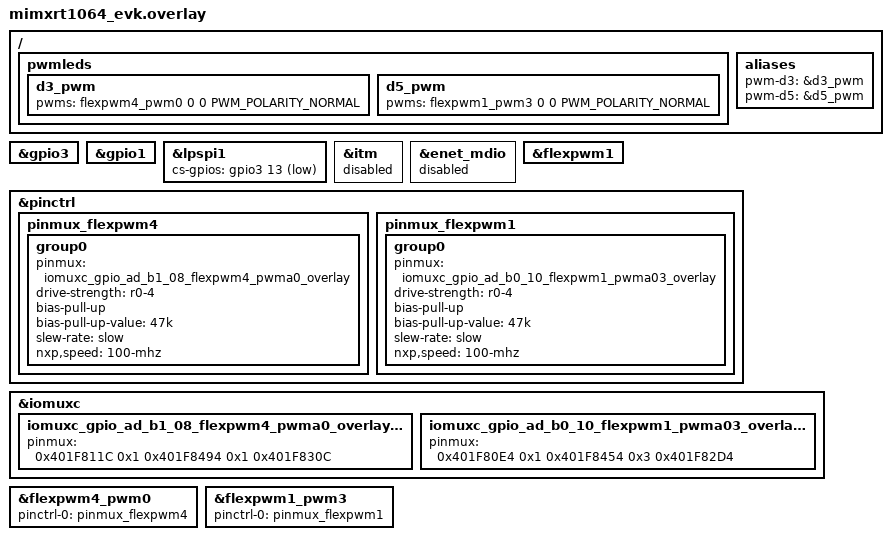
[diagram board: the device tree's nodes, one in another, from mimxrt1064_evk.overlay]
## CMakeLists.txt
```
# SPDX-License-Identifier: Apache-2.0

cmake_minimum_required(VERSION 3.20.0)

find_package(Zephyr REQUIRED HINTS $ENV{ZEPHYR_BASE})
project(serial)

if(NOT DEFINED SELECTED_PROJECT)
    message(FATAL_ERROR "Please specify a project to build with -DSELECTED_PROJECT=<PROJECT_NAME>")
endif()

if(SELECTED_PROJECT STREQUAL "I2C_OLED")
    target_sources(app PRIVATE Projects/I2C_OLED/src/main.cpp Projects/I2C_OLED/src/oled.cpp)
    target_include_directories(app PRIVATE Projects/I2C_OLED/include)

elseif(SELECTED_PROJECT STREQUAL "ST1140")
    target_sources(app PRIVATE Projects/ST1140/main.cpp)

elseif(SELECTED_PROJECT STREQUAL "HCSR04")
    target_sources(app PRIVATE Projects/HCSR04/main.cpp)

elseif(SELECTED_PROJECT STREQUAL "SPI_NRF24L01")
    target_sources(app PRIVATE Projects/SPI_NRF24L01/src/main.cpp Projects/SPI_NRF24L01/src/nrf24.cpp)
    target_include_directories(app PRIVATE Projects/SPI_NRF24L01/include)

elseif(SELECTED_PROJECT STREQUAL "UART_BRIDGE")
    target_sources(app PRIVATE Projects/UART_BRIDGE/src/main.cpp Projects/UART_BRIDGE/src/uart_bridge.cpp)
    target_include_directories(app PRIVATE Projects/UART_BRIDGE/include)

elseif(SELECTED_PROJECT STREQUAL "AHT40")
    target_sources(app PRIVATE Projects/AHT40/src/main.cpp Projects/AHT40/src/aht40.cpp)
    target_include_directories(app PRIVATE Projects/AHT40/include)

else()
    message(FATAL_ERROR "Unknown project: ${SELECTED_PROJECT}")
endif()
```

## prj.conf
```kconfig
CONFIG_PRINTK=y
CONFIG_CBPRINTF_FP_SUPPORT=y
CONFIG_CPP=y
CONFIG_GPIO=y
CONFIG_SPI=y
CONFIG_PWM=y
CONFIG_ADC=y
CONFIG_COUNTER=y
CONFIG_STD_CPP17=y
CONFIG_NEWLIB_LIBC=y
CONFIG_LOG=y
CONFIG_LOG_MODE_MINIMAL=y
```

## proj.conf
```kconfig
CONFIG_PRINTK=y
CONFIG_CBPRINTF_FP_SUPPORT=y
CONFIG_CPP=y
CONFIG_I2C=y
CONFIG_GPIO=y
CONFIG_SPI=y
```

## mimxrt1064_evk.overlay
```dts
&gpio3 {
    status = "okay";
};

&gpio1 {
    status = "okay";
};

&lpspi1 {
    status = "okay";
    cs-gpios = <&gpio3 13 GPIO_ACTIVE_LOW>;
};

&itm {
    status = "disabled";
};

&enet_mdio {
    status = "disabled";
};

&flexpwm1 {
    status = "okay";
};

&pinctrl {
    /* Konfiguracja pinmux dla GPIO_AD_B1_08 */
    pinmux_flexpwm4: pinmux_flexpwm4 {
        group0 {
            pinmux = <&iomuxc_gpio_ad_b1_08_flexpwm4_pwma0_overlay>;
            drive-strength = "r0-4";
            bias-pull-up;
            bias-pull-up-value = "47k";
            slew-rate = "slow";
            nxp,speed = "100-mhz";
        };
    };
    
    /* Konfiguracja pinmux dla GPIO_AD_B0_10 */
    pinmux_flexpwm1: pinmux_flexpwm1 {
        group0 {
            pinmux = <&iomuxc_gpio_ad_b0_10_flexpwm1_pwma03_overlay>;
            drive-strength = "r0-4";
            bias-pull-up;
            bias-pull-up-value = "47k";
            slew-rate = "slow";
            nxp,speed = "100-mhz";
        };
    };
};

/* Konfiguracja pinu GPIO_AD_B1_08 na IOMUXC_GPIO_AD_B1_08_FLEXPWM4_PWMA00 */
&iomuxc {
    iomuxc_gpio_ad_b1_08_flexpwm4_pwma0_overlay: IOMUXC_GPIO_AD_B1_08_FLEXPWM4_PWMA00 {
        pinmux = <0x401F811C 0x1 0x401F8494 0x1 0x401F830C>;
    };
};

/* Konfiguracja pinu GPIO_AD_B0_10 na IOMUXC_GPIO_AD_B0_10_FLEXPWM1_PWMA03 */
&iomuxc {
    iomuxc_gpio_ad_b0_10_flexpwm1_pwma03_overlay: IOMUXC_GPIO_AD_B0_10_FLEXPWM1_PWMA03 {
        pinmux = <0x401F80E4 0x1 0x401F8454 0x3 0x401F82D4>;
    };
};

/* Konfiguracja FLEXPWM dla GPIO_AD_B1_08 (D3)*/
&flexpwm4_pwm0 {
    status = "okay";
    pinctrl-0 = <&pinmux_flexpwm4>;
    pinctrl-names = "default";
};

/* Konfiguracja FLEXPWM dla GPIO_AD_B0_10 (D5) */
&flexpwm1_pwm3 {
    status = "okay";
    pinctrl-0 = <&pinmux_flexpwm1>;
    pinctrl-names = "default";
};

/ { 
    pwmleds {
        d3_pwm: d3_pwm {
            pwms = <&flexpwm4_pwm0 0 0 PWM_POLARITY_NORMAL>;
        };

        d5_pwm: d5_pwm {
            pwms = <&flexpwm1_pwm3 0 0 PWM_POLARITY_NORMAL>;
        };
    };
};

/ {
    aliases {
        pwm-d3 = &d3_pwm; /* PWM na D3 (GPIO_AD_B1_08) */
        pwm-d5 = &d5_pwm; /* PWM na D5 (GPIO_AD_B0_10) */
    };
};
```

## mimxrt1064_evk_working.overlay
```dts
&qtmr1_timer0 {
    status = "okay";
    mode = "kQTMR_PriSrcRiseEdge";
    primary_source = "kQTMR_ClockDivide_128";
};

&pit0_channel0 {
    status = "okay";
};

&csi {
    status = "disabled";
};

&pinmux_csi {
    group1 {
        pinmux = <>;
    };
};

&flexcan1 {
    status = "disabled";
};

&pinmux_flexcan1 {
    group0 {
        pinmux = <>;
    };
};

&pinctrl {
    pinmux_flexpwm4: pinmux_flexpwm4 {
        pinmux = <
            0x401F811C 0x1 0x401F8494 0x1 0x401F830C 0x10B0
        >;
    };
};

&flexpwm4_pwm0 {
    status = "okay";
    pinctrl-0 = <&pinmux_flexpwm4>;
    pinctrl-names = "default";
};

/ {
    aliases {
        pwm-d3 = &flexpwm4_pwm0; /* PWM na D3 (GPIO_AD_B1_08) */
    };
};
```

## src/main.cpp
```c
#include <zephyr/kernel.h>
#include <zephyr/device.h>
#include <zephyr/drivers/gpio.h>

/* Definicje dla pinów */
#define GPIO_NODE DT_NODELABEL(gpio1)
#define TRIG_PIN 17
#define ECHO_PIN 16
#define BUZZER_PIN 21

#define TRIG_FLAGS (GPIO_OUTPUT)
#define ECHO_FLAGS (GPIO_INPUT)
#define BUZZER_FLAGS (GPIO_OUTPUT)

/* Parametry dla dźwięku buzzera */
#define MIN_DISTANCE_CM 10     // Minimalna odległość do aktywacji buzzera
#define MAX_DISTANCE_CM 100    // Maksymalna odległość, przy której buzzer działa z przerwami
#define BUZZER_PULSE_MS 100    // Czas impulsu buzzera
#define BUZZER_OFF_MS 300      // Czas wyłączenia buzzera

/* Inicjalizacja urządzeń */
const struct device *gpio_dev;

/* Funkcja do mierzenia odległości */
int measure_distance() {
    uint32_t start, end;
    
    // Wysyłanie impulsu przez TRIG
    gpio_pin_set(gpio_dev, TRIG_PIN, 1);
    k_busy_wait(10);  // 10 mikrosekund
    gpio_pin_set(gpio_dev, TRIG_PIN, 0);

    // Czekanie na odbiór sygnału na pinie ECHO
    while (gpio_pin_get(gpio_dev, ECHO_PIN) == 0);
    start = k_cycle_get_32();

    while (gpio_pin_get(gpio_dev, ECHO_PIN) == 1);
    end = k_cycle_get_32();

    // Obliczenie odległości w centymetrach
    uint32_t duration = end - start;
    int distance_cm = (duration * 34300) / (2 * sys_clock_hw_cycles_per_sec());

    return distance_cm;
}

/* Funkcja kontrolująca buzzer na podstawie odległości */
void control_buzzer(int distance) {
    if (distance <= MIN_DISTANCE_CM) {
        // Przy bardzo małej odległości buzzer działa ciągle
        gpio_pin_set(gpio_dev, BUZZER_PIN, 1);
    } else if (distance <= MAX_DISTANCE_CM) {
        // Dla większej odległości buzzer działa z przerwami
        gpio_pin_set(gpio_dev, BUZZER_PIN, 1);
        k_msleep(BUZZER_PULSE_MS);
        gpio_pin_set(gpio_dev, BUZZER_PIN, 0);
        k_msleep(BUZZER_OFF_MS);
    } else {
        // Buzzer wyłączony przy większych odległościach
        gpio_pin_set(gpio_dev, BUZZER_PIN, 0);
    }
}

int main() {
    int ret;

    /* Inicjalizacja GPIO */
    gpio_dev = DEVICE_DT_GET(GPIO_NODE);
    if (!device_is_ready(gpio_dev)) {
        printk("GPIO device not ready\n");
        return 1;
    }

    /* Konfiguracja pinów */
    ret = gpio_pin_configure(gpio_dev, TRIG_PIN, TRIG_FLAGS);
    if (ret < 0) {
        printk("Failed to configure TRIG pin\n");
        return 1;
    }

    ret = gpio_pin_configure(gpio_dev, ECHO_PIN, ECHO_FLAGS);
    if (ret < 0) {
        printk("Failed to configure ECHO pin\n");
        return 1;
    }

    ret = gpio_pin_configure(gpio_dev, BUZZER_PIN, BUZZER_FLAGS);
    if (ret < 0) {
        printk("Failed to configure BUZZER pin\n");
        return 1;
    }

    printk("System initialized\n");

    while (1) {
        int distance = measure_distance();
        printk("Odległość: %d cm\n", distance);

        control_buzzer(distance);
        k_msleep(500);  // Pomiary co pół sekundy
    }
    return 0;
}
```

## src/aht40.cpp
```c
#include "aht40.h"
#include <zephyr/drivers/i2c.h>
#include <zephyr/logging/log.h>

LOG_MODULE_REGISTER(AHT40, LOG_LEVEL_DBG);

bool aht40_init(const struct device *i2c_dev) {
    uint8_t init_cmd[3] = {0xBE, 0x08, 0x00};
    int ret = i2c_write(i2c_dev, init_cmd, sizeof(init_cmd), AHT40_I2C_ADDRESS);
    if (ret < 0) {
        LOG_ERR("Failed to initialize AHT40: %d", ret);
        return false;
    }
    k_msleep(10);  // Allow time for sensor to initialize
    return true;
}

bool aht40_read_data(const struct device *i2c_dev, float *temperature, float *humidity) {
    uint8_t trigger_cmd[3] = {0xAC, 0x33, 0x00};
    uint8_t data[6];
    int ret;

    // Trigger measurement
    ret = i2c_write(i2c_dev, trigger_cmd, sizeof(trigger_cmd), AHT40_I2C_ADDRESS);
    if (ret < 0) {
        LOG_ERR("Failed to trigger AHT40 measurement: %d", ret);
        return false;
    }

    k_msleep(80);  // Wait for measurement to complete

    // Read the measurement data
    ret = i2c_read(i2c_dev, data, 6, AHT40_I2C_ADDRESS);
    if (ret < 0) {
        LOG_ERR("Failed to read data from AHT40: %d", ret);
        return false;
    }

    // Process the raw data to extract temperature and humidity
    uint32_t humidity_raw = ((data[1] << 12) | (data[2] << 4) | (data[3] >> 4));
    uint32_t temperature_raw = ((data[3] & 0x0F) << 16) | (data[4] << 8) | data[5];

    *humidity = ((float)humidity_raw / 1048576) * 100;
    *temperature = ((float)temperature_raw / 1048576) * 200 - 50;

    return true;
}
```

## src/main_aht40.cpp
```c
#include <zephyr/kernel.h>
#include <zephyr/device.h>
#include <zephyr/drivers/gpio.h>

#include "aht40.h"

int main(void) {
    const struct device *i2c_dev = DEVICE_DT_GET(DT_NODELABEL(lpi2c1));
    float temperature, humidity;

    if (!device_is_ready(i2c_dev)) {
        printk("I2C device not ready\n");
        return 1;
    }

    if (!aht40_init(i2c_dev)) {
        printk("Failed to initialize AHT40 sensor\n");
        return 1;
    }

    while (true) {
        if (aht40_read_data(i2c_dev, &temperature, &humidity)) {
            printk("Temperature: %.2f°C, Humidity: %.2f%%\n", static_cast<double>(temperature), static_cast<double>(humidity));

        } else {
            printk("Failed to read data from AHT40 sensor\n");
        }

        k_sleep(K_SECONDS(5));
    }
    return 0;
}
```

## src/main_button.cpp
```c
#include <zephyr/kernel.h>
#include <zephyr/device.h>
#include <zephyr/devicetree.h>
#include <zephyr/drivers/gpio.h>

/* Definitions for D15 and D14 */
#define GPIO_NODE DT_NODELABEL(gpio1)
#define D15_PIN 16  // LED pin
#define D14_PIN 17  // Button pin

#define D15_FLAGS (GPIO_OUTPUT | GPIO_ACTIVE_LOW)  // LED starts OFF
#define D14_FLAGS (GPIO_INPUT | GPIO_PULL_UP | GPIO_ACTIVE_LOW)  // Button with pull-up

#define DEBOUNCE_DELAY_MS 50

int main()
{
    const struct device *gpio_dev;
    int ret;
    int button_state, last_button_state = 1;
    bool led_state = false;

    /* Get GPIO device */
    gpio_dev = DEVICE_DT_GET(GPIO_NODE);
    if (!device_is_ready(gpio_dev)) {
        printk("GPIO device not ready\n");
        return 1;
    }

    /* Configure pin D15 as output for LED */
    ret = gpio_pin_configure(gpio_dev, D15_PIN, D15_FLAGS);
    if (ret < 0) {
        printk("Failed to configure D15 pin\n");
        return 1;
    }

    /* Configure pin D14 as input with pull-up */
    ret = gpio_pin_configure(gpio_dev, D14_PIN, D14_FLAGS);
    if (ret < 0) {
        printk("Failed to configure D14 pin\n");
        return 1;
    }

    printk("System initialized\n");

    while (1) {
        button_state = gpio_pin_get(gpio_dev, D14_PIN);

        if (button_state != last_button_state) {
            k_msleep(DEBOUNCE_DELAY_MS);

            button_state = gpio_pin_get(gpio_dev, D14_PIN);
            if (button_state == 0) {
                led_state = !led_state;
                gpio_pin_set(gpio_dev, D15_PIN, led_state ? 0 : 1);
            }
        }

        last_button_state = button_state;
        k_msleep(10);
    }
    return 0;
}
```

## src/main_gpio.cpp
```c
#include <zephyr/kernel.h>
#include <zephyr/device.h>
#include <zephyr/devicetree.h>
#include <zephyr/drivers/gpio.h>

/* Definicje dla D15 */
#define D15_GPIO_NODE DT_NODELABEL(gpio1)
#define D15_PIN 27

/* Opcjonalnie, jeśli potrzebujesz flag, możesz je zdefiniować */
#define D15_FLAGS GPIO_ACTIVE_LOW

int main(void)
{
    const struct device *gpio_dev;
    int ret;

    /* Pobierz urządzenie GPIO */
    gpio_dev = DEVICE_DT_GET(D15_GPIO_NODE);
    if (!device_is_ready(gpio_dev)) {
        printk("GPIO device not ready\n");
        return 1;
    }

    /* Skonfiguruj pin D15 jako wyjście */
    ret = gpio_pin_configure(gpio_dev, D15_PIN, GPIO_OUTPUT_ACTIVE | D15_FLAGS);
    if (ret < 0) {
        printk("Failed to configure GPIO pin\n");
        return 1;
    }

    while (1) {
        gpio_pin_toggle(gpio_dev, D15_PIN);
        k_msleep(500);
    }
    return 0;
}
```

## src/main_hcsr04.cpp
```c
#include <zephyr/kernel.h>
#include <zephyr/device.h>
#include <zephyr/drivers/gpio.h>

/* Definicje dla pinów */
#define GPIO_NODE DT_NODELABEL(gpio1)
#define TRIG_PIN 17
#define ECHO_PIN 16
#define BUZZER_PIN 21

#define TRIG_FLAGS (GPIO_OUTPUT)
#define ECHO_FLAGS (GPIO_INPUT)
#define BUZZER_FLAGS (GPIO_OUTPUT)

/* Parametry dla dźwięku buzzera */
#define MIN_DISTANCE_CM 10          // Minimalna odległość do aktywacji buzzera
#define MAX_DISTANCE_CM 20          // Maksymalna odległość, przy której buzzer działa z przerwami
#define SHORT_BUZZER_PULSE_MS 10    // Czas impulsu buzzera (blisko)
#define LONG_BUZZER_PULSE_MS 200    // Czas impulsu buzzera (daleko)
#define ZERO_DISTANCE 2000          // Dystans który odpowiada zerwoej odległości (należy dopasować do odczytów)

const struct device *gpio_dev;

int measure_distance() {
    uint32_t start, end;
    // gpio_pin_set(gpio_dev, TRIG_PIN, 0);
    // k_busy_wait(10);

    gpio_pin_set(gpio_dev, TRIG_PIN, 1);
    k_busy_wait(10);  // 10 mikrosekund
    gpio_pin_set(gpio_dev, TRIG_PIN, 0);

    // Czekanie na odbiór sygnału na pinie ECHO
    while (gpio_pin_get(gpio_dev, ECHO_PIN) == 0);
    start = k_cycle_get_32();

    while (gpio_pin_get(gpio_dev, ECHO_PIN) == 1);
    end = k_cycle_get_32();

    // Obliczenie odległości
    int duration = end - start;
    double time_s = (double)duration / sys_clock_hw_cycles_per_sec();
    printk("Czas: %.2f\n", time_s);
    int distance_cm = (int)((time_s * 34300) / 2);
    return distance_cm;
}


void control_buzzer(int distance) {
    if (distance >= ZERO_DISTANCE) {
        // Ciągłe włączenie buzzera, gdy obiekt jest bardzo blisko (>= 2000 cm)
        gpio_pin_set(gpio_dev, BUZZER_PIN, 1);
    } else if (distance <= MIN_DISTANCE_CM) {
        // Szybkie pikanie dla minimalnej odległości
        gpio_pin_set(gpio_dev, BUZZER_PIN, 1);
        k_msleep(SHORT_BUZZER_PULSE_MS);
        gpio_pin_set(gpio_dev, BUZZER_PIN, 0);
        k_msleep(SHORT_BUZZER_PULSE_MS);
    } else if (distance <= MAX_DISTANCE_CM) {
        // Wolniejsze pikanie dla większej odległości (w zakresie MAX_DISTANCE_CM)
        gpio_pin_set(gpio_dev, BUZZER_PIN, 1);
        k_msleep(LONG_BUZZER_PULSE_MS);
        gpio_pin_set(gpio_dev, BUZZER_PIN, 0);
        k_msleep(LONG_BUZZER_PULSE_MS);
    } else {
        // Wyłączenie buzzera, gdy obiekt jest poza zasięgiem określonych wartości
        gpio_pin_set(gpio_dev, BUZZER_PIN, 0);
    }
}


int main() {
    int ret;

    /* Inicjalizacja GPIO */
    gpio_dev = DEVICE_DT_GET(GPIO_NODE);
    if (!device_is_ready(gpio_dev)) {
        printk("GPIO device not ready\n");
        return 1;
    }

    /* Konfiguracja pinów */
    ret = gpio_pin_configure(gpio_dev, TRIG_PIN, TRIG_FLAGS);
    if (ret < 0) {
        printk("Failed to configure TRIG pin\n");
        return 1;
    }

    ret = gpio_pin_configure(gpio_dev, ECHO_PIN, ECHO_FLAGS);
    if (ret < 0) {
        printk("Failed to configure ECHO pin\n");
        return 1;
    }

    ret = gpio_pin_configure(gpio_dev, BUZZER_PIN, BUZZER_FLAGS);
    if (ret < 0) {
        printk("Failed to configure BUZZER pin\n");
        return 1;
    }

    printk("System initialized\n");

    while (1) {
        int distance = measure_distance();
        if (distance != -1) {
            printk("Odległość: %d cm\n", distance);
            control_buzzer(distance);
        } else {
            printk("Błąd pomiaru\n");
        }
        k_msleep(500);
    }
    return 0;
}
```

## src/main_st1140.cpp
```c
#include <zephyr/kernel.h>
#include <zephyr/device.h>
#include <zephyr/drivers/gpio.h>

/* Definicje dla pinów */
#define GPIO_NODE DT_NODELABEL(gpio1)
#define SENSOR_PIN -1                   // znajdź poprawny pin
#define SENSOR_FLAGS -1                 // dodaj odpowiednie flagi (FLAGA_1 | FLAGA_2 | FLAGA_3 ...)

const struct device *gpio_dev;

int main() {
    int ret;

    /* Inicjalizacja GPIO */
    gpio_dev = DEVICE_DT_GET(GPIO_NODE);
    if (!device_is_ready(gpio_dev)) {
        printk("GPIO device not ready\n");
        return 1;
    }

    /* Konfiguracja pinu czujnika jako wejściowego */
    ret = gpio_pin_configure(gpio_dev, SENSOR_PIN, SENSOR_FLAGS);
    if (ret < 0) {
        printk("Failed to configure sensor pin\n");
        return 1;
    }

    printk("System initialized\n");

    while (1) {
        // @TODO 
        // Napisz kod odczytujący dane z czujnika ST1140
    }
    return 0;
}
```
